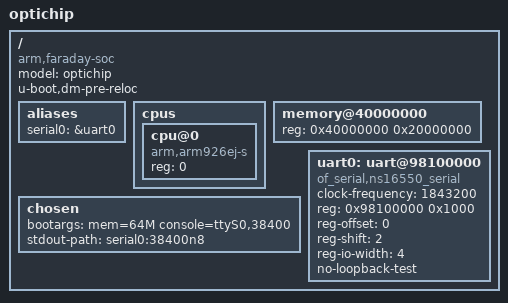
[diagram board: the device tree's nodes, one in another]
/*
 * Copyright (C) 2014 Faraday, Inc. (www.faraday-tech.com)
 *
 * This program is free software; you can redistribute it and/or modify
 * it under the terms of the GNU General Public License version 2 as
 * published by the Free Software Foundation.
 */
 /dts-v1/;
/  {
	model = "optichip";
	compatible = "arm,faraday-soc";
        u-boot,dm-pre-reloc;
	#address-cells = <1>;
	#size-cells = <1>;
	
	aliases {
		serial0 = &uart0;
	};
	
	cpus {
		#address-cells = <1>;
		#size-cells = <0>;

		cpu@0 {
			device_type = "cpu";
			compatible = "arm,arm926ej-s";
			reg = <0>;
		};
	};

	memory@40000000 {
		device_type = "memory";
		reg = <0x40000000 0x20000000>;
	};
		
	
	chosen {
		bootargs = "mem=64M console=ttyS0,38400";	
		stdout-path = "serial0:38400n8";
	};
		
	uart0: uart@98100000 {
		compatible = "of_serial,ns16550_serial", "ns16550";
		clock-frequency = <1843200>;
		reg = <0x98100000 0x1000>;		
		reg-offset = <0>;
		reg-shift = <2>;
		reg-io-width = <4>;
		no-loopback-test;
	};
 };
